# cslr_adcc5509_001 register map
Vendor: Texas Instruments
Peripheral module from a debugger description file.
Registers are 16-bit, access per field, reset 0x0 unless marked. A register's access mark holds for its fields unless they carry their own. Offsets are as the file gives them; lines under a group give offsets from that group; [hi:lo] are bit positions; {n}, {i} and the like mark numbered series; 'fields as' and 'values as' point back to an identical list; <NAME> marks a mode.

## ADC — Analog-to-Digital Converter
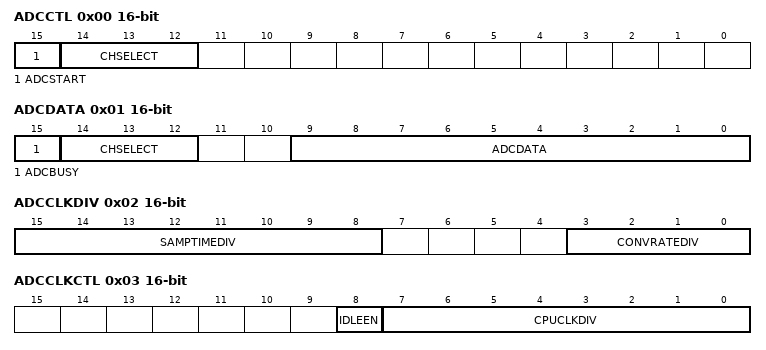
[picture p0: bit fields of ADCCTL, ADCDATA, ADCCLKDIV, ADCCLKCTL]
0x00 ADCCTL (reset mask 0x8FFF) — ADC control register
  [15] ADCSTART rw — Start of conversion bit
    0=Writing 0 has no effect; 1=Start conversion cycle
  [14:12] CHSELECT rw — Analog input channel select bits.
    {v}=Analog input AIN{v} is selected (v=0..3)
0x01 ADCDATA ro (reset mask 0x8FFF)
  [15] ADCBUSY — ADC busy bit
    0=ADC data is available; 1=ADC is busy performing a conversion
  [14:12] CHSELECT — Channel select bits.
    {v}=Analog input AIN{v} is selected (v=0..3)
  [9:0] ADCDATA — ADC data bits.
0x02 ADCCLKDIV (reset mask 0xFFF0) — ADC Clock Divider Register
  [15:8] SAMPTIMEDIV rw — Sample and hold time divider bits.
  [3:0] CONVRATEDIV rw — Conversion clock rate divider bits.
    0=Conversion clock = ADC clock divided by 2; 1=Conversion clock = ADC clock divided by 4; 2=Conversion clock = ADC clock divided by 6; 3=Conversion clock = ADC clock divided by 8; 4=Conversion clock = ADC clock divided by 10; 5=Conversion clock = ADC clock divided by 12; 6=Conversion clock = ADC clock divided by 14; 7=Conversion clock = ADC clock divided by 16; 8=Conversion clock = ADC clock divided by 18; 9=Conversion clock = ADC clock divided by 20; 10=Conversion clock = ADC clock divided by 22; 11=Conversion clock = ADC clock divided by 24; 12=Conversion clock = ADC clock divided by 26; 13=Conversion clock = ADC clock divided by 28; 14=Conversion clock = ADC clock divided by 30; 15=Conversion clock = ADC clock divided by 32
0x03 ADCCLKCTL (reset mask 0xFF00) — ADC Clock Control Register
  [8] IDLEEN rw — Idle enable bit for the ADC.
    0=The ADC cannot be placed in the idle state; 1=If the peripherals domain is idle, the ADC is in the idle state
  [7:0] CPUCLKDIV rw — CPU clock divider bits.
